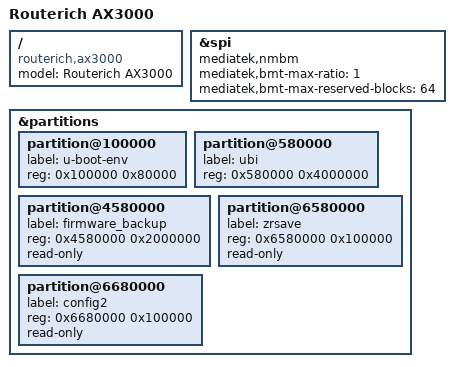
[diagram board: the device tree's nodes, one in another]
// SPDX-License-Identifier: GPL-2.0-only OR MIT

#include "mt7981b-routerich-ax3000-common.dtsi"

/ {
	model = "Routerich AX3000";
	compatible = "routerich,ax3000", "mediatek,mt7981";
};

&spi {
	mediatek,nmbm;
	mediatek,bmt-max-ratio = <1>;
	mediatek,bmt-max-reserved-blocks = <64>;
};

&partitions {
	partition@100000 {
		label = "u-boot-env";
		reg = <0x100000 0x80000>;
	};

	partition@580000 {
		label = "ubi";
		reg = <0x580000 0x4000000>;
	};

	partition@4580000 {
		label = "firmware_backup";
		reg = <0x4580000 0x2000000>;
		read-only;
	};

	partition@6580000 {
		label = "zrsave";
		reg = <0x6580000 0x100000>;
		read-only;
	};

	partition@6680000 {
		label = "config2";
		reg = <0x6680000 0x100000>;
		read-only;
	};
};
